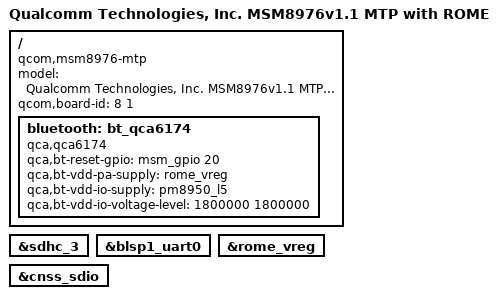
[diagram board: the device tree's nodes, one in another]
/*
 * Copyright (c) 2015, The Linux Foundation. All rights reserved.
 *
 * This program is free software; you can redistribute it and/or modify
 * it under the terms of the GNU General Public License version 2 and
 * only version 2 as published by the Free Software Foundation.
 *
 * This program is distributed in the hope that it will be useful,
 * but WITHOUT ANY WARRANTY; without even the implied warranty of
 * MERCHANTABILITY or FITNESS FOR A PARTICULAR PURPOSE.  See the
 * GNU General Public License for more details.
 */

/dts-v1/;
#include "msm8976-v1.1.dtsi"
#include "msm8976-mtp.dtsi"

/ {
	model = "Qualcomm Technologies, Inc. MSM8976v1.1 MTP with ROME";
	compatible = "qcom,msm8976-mtp", "qcom,msm8976", "qcom,mtp";
	qcom,board-id= <8 1>;
};

&sdhc_3 {
	status = "ok";
};

&blsp1_uart0 {
	status = "ok";
};

/ {
	bluetooth: bt_qca6174 {
		compatible = "qca,qca6174";
		qca,bt-reset-gpio = <&msm_gpio 20 0>; /* BT_EN */
		qca,bt-vdd-pa-supply = <&rome_vreg>;
		qca,bt-vdd-io-supply = <&pm8950_l5>;
		qca,bt-vdd-io-voltage-level = <1800000 1800000>;
	};
};

&rome_vreg {
	status = "ok";
};

&cnss_sdio {
	status = "ok";
};
